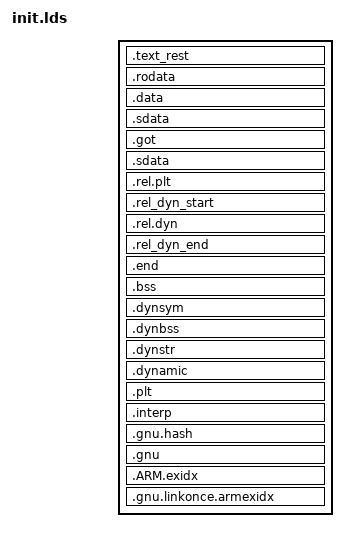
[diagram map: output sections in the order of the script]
/* SPDX-License-Identifier: GPL-2.0+ */
/*
 * Copyright (c) 2004-2008 Texas Instruments
 *
 * (C) Copyright 2002
 * Gary Jennejohn, DENX Software Engineering, <garyj@denx.de>
 */


OUTPUT_FORMAT("elf32-littlearm", "elf32-littlearm", "elf32-littlearm")
OUTPUT_ARCH(arm)
ENTRY(_start)
SECTIONS
{
	. = 0x82800000;

	. = ALIGN(4);
	.text_rest :
	{
		*(.text*)
	}

	. = ALIGN(4);
	.rodata : { *(SORT_BY_ALIGNMENT(SORT_BY_NAME(.rodata*))) }

	. = ALIGN(4);
	.data : {
		*(.data*)
	}

	. = ALIGN(4);
	.sdata : {
		*(.sdata*)
	}

	. = ALIGN(4);
	.got : {
		*(.got)
	}

	. = ALIGN(4);
	.sdata : {
		*(.sdata*)
	}

	. = ALIGN(4);
	.rel.plt :
	{
		*(.rel.plt)
	}

	.rel_dyn_start :
	{
		*(.__rel_dyn_start)
	}

	.rel.dyn : {
		*(.rel*)
	}

	.rel_dyn_end :
	{
		*(.__rel_dyn_end)
	}

	.end :
	{
		*(.__end)
	}

	.bss  : {
		__bss_start = .;
		*(.bss*)
		 . = ALIGN(4);
		__bss_end = .;
	}

	.dynsym : { *(.dynsym) }
	.dynbss : { *(.dynbss) }
	.dynstr : { *(.dynstr*) }
	.dynamic : { *(.dynamic*) }
	.plt : { *(.plt*) }
	.interp : { *(.interp*) }
	.gnu.hash : { *(.gnu.hash) }
	.gnu : { *(.gnu*) }
	.ARM.exidx : { *(.ARM.exidx*) }
	.gnu.linkonce.armexidx : { *(.gnu.linkonce.armexidx.*) }
}
